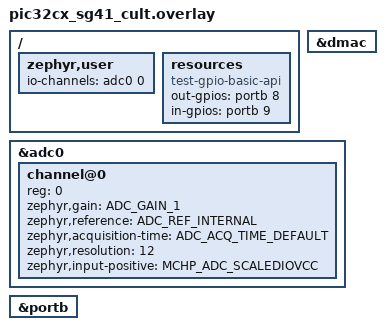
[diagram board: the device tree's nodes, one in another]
/*
 * Copyright (c) 2025 Microchip Technology Inc.
 *
 * SPDX-License-Identifier: Apache-2.0
 */

tst_dma0: &dmac {
	status = "okay";
};

/ {
	zephyr,user {
		io-channels = <&adc0 0>;
	};
};

&adc0 {
	#address-cells = <1>;
	#size-cells = <0>;
	status = "okay";
	channel@0 {
		reg = <0>;
		zephyr,gain = "ADC_GAIN_1";
		zephyr,reference = "ADC_REF_INTERNAL";
		zephyr,acquisition-time = <ADC_ACQ_TIME_DEFAULT>;
		zephyr,resolution = <12>;
		zephyr,input-positive = <MCHP_ADC_SCALEDIOVCC>;
	};
};

/ {
	resources {
		compatible = "test-gpio-basic-api";
		out-gpios = <&portb 8 0>;
		in-gpios = <&portb 9 0>;
	};
};

&portb {
	status = "okay";
};
